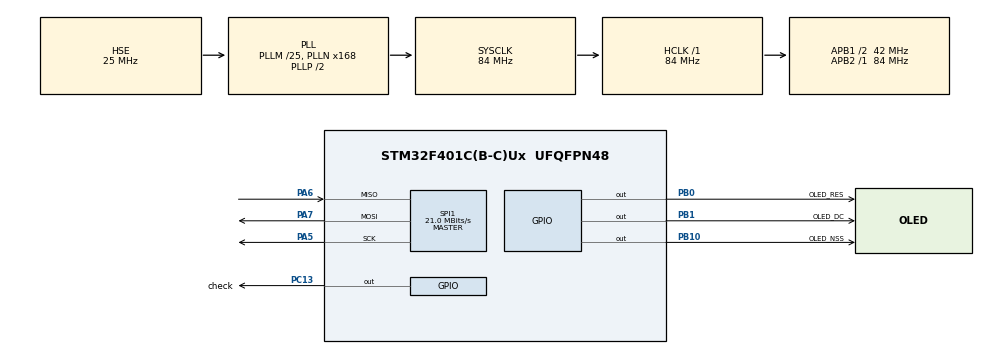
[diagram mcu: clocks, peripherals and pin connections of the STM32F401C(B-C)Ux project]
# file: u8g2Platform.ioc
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Mcu.Family=STM32F4
Mcu.Name=STM32F401C(B-C)Ux
Mcu.Package=UFQFPN48
NVIC.PriorityGroup=NVIC_PRIORITYGROUP_4
PA5.Mode=Full_Duplex_Master
PA5.Signal=SPI1_SCK
PA6.Mode=Full_Duplex_Master
PA6.Signal=SPI1_MISO
PA7.Mode=Full_Duplex_Master
PA7.Signal=SPI1_MOSI
PB0.GPIO_Label=OLED_RES
PB0.Signal=GPIO_Output
PB1.GPIO_Label=OLED_DC
PB1.Signal=GPIO_Output
PB10.GPIO_Label=OLED_NSS
PB10.Signal=GPIO_Output
PC13-ANTI_TAMP.GPIO_Label=check
PC13-ANTI_TAMP.GPIO_PuPd=GPIO_PULLUP
PC13-ANTI_TAMP.Signal=GPIO_Output
PH0\ -\ OSC_IN.Mode=HSE-External-Oscillator
PH0\ -\ OSC_IN.Signal=RCC_OSC_IN
PH1\ -\ OSC_OUT.Mode=HSE-External-Oscillator
PH1\ -\ OSC_OUT.Signal=RCC_OSC_OUT
ProjectManager.HeapSize=0x200
ProjectManager.StackSize=0x400
ProjectManager.TargetToolchain=SW4STM32
RCC.48MHZClocksFreq_Value=42000000
RCC.AHBFreq_Value=84000000
RCC.APB1CLKDivider=RCC_HCLK_DIV2
RCC.APB1Freq_Value=42000000
RCC.APB1TimFreq_Value=84000000
RCC.APB2Freq_Value=84000000
RCC.APB2TimFreq_Value=84000000
RCC.CortexFreq_Value=84000000
RCC.HCLKFreq_Value=84000000
RCC.HSE_VALUE=25000000
RCC.HSI_VALUE=16000000
RCC.LSE_VALUE=32768
RCC.PLLM=25
RCC.PLLN=168
RCC.PLLSourceVirtual=RCC_PLLSOURCE_HSE
RCC.SYSCLKFreq_VALUE=84000000
RCC.SYSCLKSource=RCC_SYSCLKSOURCE_PLLCLK
RCC.VCOOutputFreq_Value=168000000
SPI1.BaudRatePrescaler=SPI_BAUDRATEPRESCALER_4
SPI1.CLKPhase=SPI_PHASE_2EDGE
SPI1.CLKPolarity=SPI_POLARITY_HIGH
SPI1.CalculateBaudRate=21.0 MBits/s
SPI1.Direction=SPI_DIRECTION_2LINES
SPI1.Mode=SPI_MODE_MASTER
SPI1.VirtualType=VM_MASTER
board=custom

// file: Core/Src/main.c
/* USER CODE BEGIN Header */
/**
  ******************************************************************************
  * @file           : main.c
  * @brief          : Main program body
  ******************************************************************************
  * @attention
  *
  * <h2><center>&copy; Copyright (c) 2021 STMicroelectronics.
  * All rights reserved.</center></h2>
  *
  * This software component is licensed by ST under BSD 3-Clause license,
  * the "License"; You may not use this file except in compliance with the
  * License. You may obtain a copy of the License at:
  *                        opensource.org/licenses/BSD-3-Clause
  *
  ******************************************************************************
  */
/* USER CODE END Header */
#include "main.h"
#include "spi.h"
#include "gpio.h"
/* USER CODE BEGIN Includes */
#include "OLEDscreen.h"
/* USER CODE END Includes */

void SystemClock_Config(void);

int main(void)
{

  /* MCU Configuration--------------------------------------------------------*/

  /* Reset of all peripherals, Initializes the Flash interface and the Systick. */
  HAL_Init();

  /* Configure the system clock */
  SystemClock_Config();

  /* Initialize all configured peripherals */
  MX_GPIO_Init();
  MX_SPI1_Init();
  /* USER CODE BEGIN 2 */
    u8g2_Setup_ssd1306_128x64_noname_1(&u8g2, U8G2_R0, u8x8_byte_4wire_hw_spi, u8x8_stm32_gpio_and_delay);
    u8g2_InitDisplay(&u8g2);
    u8g2_SetPowerSave(&u8g2, 0);
  /* USER CODE END 2 */

  /* Infinite loop */
  while (1)
  {
      u8g2_FirstPage(&u8g2);
      do
      {
          u8g2_SetFont(&u8g2, u8g2_font_courR12_tf);
          u8g2_DrawStr(&u8g2, 15, 15, "SAST Electronics");
          u8g2_DrawStr(&u8g2, 40, 45, "hello STM32!");
      } while (u8g2_NextPage(&u8g2));
  }
}

void SystemClock_Config(void)
{
  RCC_OscInitTypeDef RCC_OscInitStruct = {0};
  RCC_ClkInitTypeDef RCC_ClkInitStruct = {0};

  /** Configure the main internal regulator output voltage
  */
  __HAL_RCC_PWR_CLK_ENABLE();
  __HAL_PWR_VOLTAGESCALING_CONFIG(PWR_REGULATOR_VOLTAGE_SCALE2);
  /** Initializes the RCC Oscillators according to the specified parameters
  * in the RCC_OscInitTypeDef structure.
  */
  RCC_OscInitStruct.OscillatorType = RCC_OSCILLATORTYPE_HSE;
  RCC_OscInitStruct.HSEState = RCC_HSE_ON;
  RCC_OscInitStruct.PLL.PLLState = RCC_PLL_ON;
  RCC_OscInitStruct.PLL.PLLSource = RCC_PLLSOURCE_HSE;
  RCC_OscInitStruct.PLL.PLLM = 25;
  RCC_OscInitStruct.PLL.PLLN = 168;
  RCC_OscInitStruct.PLL.PLLP = RCC_PLLP_DIV2;
  RCC_OscInitStruct.PLL.PLLQ = 4;
  if (HAL_RCC_OscConfig(&RCC_OscInitStruct) != HAL_OK)
  {
    Error_Handler();
  }
  /** Initializes the CPU, AHB and APB buses clocks
  */
  RCC_ClkInitStruct.ClockType = RCC_CLOCKTYPE_HCLK|RCC_CLOCKTYPE_SYSCLK
                              |RCC_CLOCKTYPE_PCLK1|RCC_CLOCKTYPE_PCLK2;
  RCC_ClkInitStruct.SYSCLKSource = RCC_SYSCLKSOURCE_PLLCLK;
  RCC_ClkInitStruct.AHBCLKDivider = RCC_SYSCLK_DIV1;
  RCC_ClkInitStruct.APB1CLKDivider = RCC_HCLK_DIV2;
  RCC_ClkInitStruct.APB2CLKDivider = RCC_HCLK_DIV1;

  if (HAL_RCC_ClockConfig(&RCC_ClkInitStruct, FLASH_LATENCY_2) != HAL_OK)
  {
    Error_Handler();
  }
}

void Error_Handler(void)
{
  __disable_irq();
  while (1)
  {
  }
}

/************************ (C) COPYRIGHT STMicroelectronics *****END OF FILE****/
